AUTOSAR XML (schema 4-3-0)
standard types defined: UINT32, SINT32, UINT16, SINT16, UINT8, SINT8
package /PythonEtreeGenerated/SYSTEM
  system System
package /PythonEtreeGenerated/Odrive_DB
  can cluster OdriveCluster: baudrate=250000, protocol-name=CAN, speed=250000
    can physical channel CANChannel: comm-connectors=[Connector_Motor1, Connector_Main]
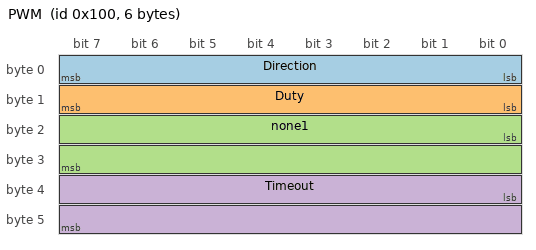
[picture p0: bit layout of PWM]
      frame PWM: id 0x100, from Main, to Motor1, frame-length=6, can-addressing-mode=STANDARD, can-frame-tx-behavior=CAN-20
        pdu PWM: length=6
          signal Direction: start 0, 8 bit, little-endian, data-type-policy=OVERRIDE, base-type=SINT8, compu {phys=raw}, to Motor1 Main
          signal Duty: start 8, 8 bit, little-endian, data-type-policy=OVERRIDE, base-type=UINT8, compu {phys=raw}, to Motor1 Main
          signal none1: start 16, 16 bit, little-endian, data-type-policy=OVERRIDE, base-type=UINT16, compu {phys=raw}, to Motor1
          signal Timeout: start 32, 16 bit, little-endian, data-type-policy=OVERRIDE, base-type=UINT16, compu {phys=raw}, to Motor1
      frame Position: id 0x101, from Main, to Motor1, frame-length=6, can-addressing-mode=STANDARD, can-frame-tx-behavior=CAN-20
        pdu Position: length=6
          signal target_pos: start 0, 32 bit, little-endian, data-type-policy=OVERRIDE, base-type=SINT32, compu {phys=raw}, to Motor1
          signal Timeout: start 32, 16 bit, little-endian, data-type-policy=OVERRIDE, base-type=UINT16, compu {phys=raw}, to Motor1
      frame Speed: id 0x102, from Main, to Motor1, frame-length=6, can-addressing-mode=STANDARD, can-frame-tx-behavior=CAN-20
        pdu Speed: length=6
          signal target_speed: start 0, 32 bit, little-endian, data-type-policy=OVERRIDE, base-type=SINT32, compu {phys=raw}, to Motor1
          signal Timeout: start 32, 16 bit, little-endian, data-type-policy=OVERRIDE, base-type=UINT16, compu {phys=raw}, to Motor1
      frame PID1: id 0x10A, from Main, to Motor1, frame-length=8, can-addressing-mode=STANDARD, can-frame-tx-behavior=CAN-20
        pdu PID1: length=8
          signal PID_kP: start 0, 32 bit, little-endian, data-type-policy=OVERRIDE, base-type=IEEE754, compu {phys=raw}, to Motor1
          signal PID_kI: start 32, 32 bit, little-endian, data-type-policy=OVERRIDE, base-type=IEEE754, compu {phys=raw}, to Motor1
      frame PID2: id 0x10B, from Main, to Motor1, frame-length=8, can-addressing-mode=STANDARD, can-frame-tx-behavior=CAN-20
        pdu PID2: length=8
          signal PID_kD: start 0, 32 bit, little-endian, data-type-policy=OVERRIDE, base-type=IEEE754, compu {phys=raw}, to Motor1
          signal PID_max: start 32, 32 bit, little-endian, data-type-policy=OVERRIDE, base-type=IEEE754, compu {phys=raw}, to Motor1
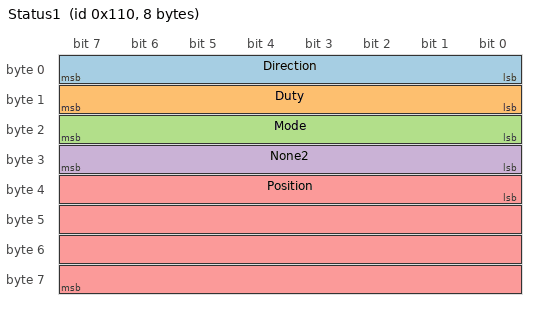
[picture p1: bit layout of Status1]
      frame Status1: id 0x110, from Motor1, to Main, frame-length=8, can-addressing-mode=STANDARD, can-frame-tx-behavior=CAN-20
        pdu Status1: length=8
          signal Direction: start 0, 8 bit, little-endian, data-type-policy=OVERRIDE, base-type=SINT8, compu {phys=raw}, to Motor1 Main
          signal Duty: start 8, 8 bit, little-endian, data-type-policy=OVERRIDE, base-type=UINT8, compu {phys=raw}, to Motor1 Main
          signal Mode: start 16, 8 bit, little-endian, data-type-policy=OVERRIDE, base-type=UINT8, compu {phys=raw}, to Main
          signal None2: start 24, 8 bit, little-endian, data-type-policy=OVERRIDE, base-type=UINT8, compu {phys=raw}, to Main
          signal Position: start 32, 32 bit, little-endian, data-type-policy=OVERRIDE, base-type=SINT32, compu {phys=raw}, to Main
      frame Status2: id 0x111, from Motor1, to Main, frame-length=8, can-addressing-mode=STANDARD, can-frame-tx-behavior=CAN-20
        pdu Status2: length=8
          signal VBAT: start 0, 32 bit, little-endian, data-type-policy=OVERRIDE, base-type=IEEE754, compu {phys=raw}, to Main
          signal Target: start 32, 32 bit, little-endian, data-type-policy=OVERRIDE, base-type=SINT32, compu {phys=raw}, to Main
package /PythonEtreeGenerated/ECU_INSTANCES
  ecu instance Motor1
    can communication controller Controller_Motor1
    can communication connector Connector_Motor1: comm-controller=Controller_Motor1
  ecu instance Main
    can communication controller Controller_Main
    can communication connector Connector_Main: comm-controller=Controller_Main
package /PythonEtreeGenerated/I_SIGNALS
  4 x i signal, all with data-type-policy=OVERRIDE:
    Direction: length=8, base-type=SINT8, system-signal=SYSTEM_SIGNALS/Direction
    Duty: length=8, base-type=UINT8, system-signal=SYSTEM_SIGNALS/Duty
    Timeout: length=16, base-type=UINT16, system-signal=SYSTEM_SIGNALS/Timeout
    Timeout: length=16, base-type=UINT16, system-signal=SYSTEM_SIGNALS/Timeout
package /PythonEtreeGenerated/BASE_TYPES
  base type IEEE754: base-type-size=32, base-type-encoding=IEEE754
package /PythonEtreeGenerated/COMPUMETHODS
  compu method FACTOR_0_1: phys=raw*0.1
  compu method FACTOR_0_01: phys=raw*0.01
package /PythonEtreeGenerated/SYSTEM_SIGNALS
  4 x system signal, all with compu {phys=raw}:
    Direction
    Duty
    Timeout
    Timeout
